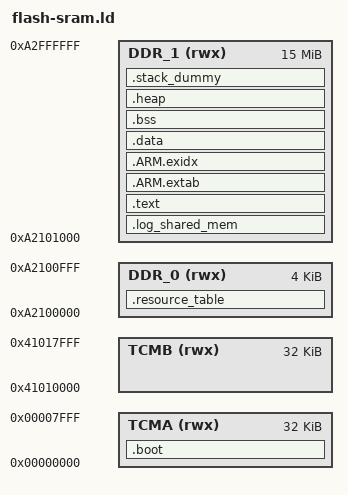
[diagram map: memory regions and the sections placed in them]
/****************************************************************************
 * boards/arm/k5-j721e/beaglebone-ai64-k5/scripts/flash-sram.ld
 *
 * Licensed to the Apache Software Foundation (ASF) under one or more
 * contributor license agreements.  See the NOTICE file distributed with
 * this work for additional information regarding copyright ownership.  The
 * ASF licenses this file to you under the Apache License, Version 2.0 (the
 * "License"); you may not use this file except in compliance with the
 * License.  You may obtain a copy of the License at
 *
 *   http://www.apache.org/licenses/LICENSE-2.0
 *
 * Unless required by applicable law or agreed to in writing, software
 * distributed under the License is distributed on an "AS IS" BASIS, WITHOUT
 * WARRANTIES OR CONDITIONS OF ANY KIND, either express or implied.  See the
 * License for the specific language governing permissions and limitations
 * under the License.
 *
 ****************************************************************************/

__DDR_START__ = 0xA2000000;

MEMORY
{
  TCMA (rwx) : ORIGIN = 0x00000000, LENGTH = 32K
  TCMB (rwx) : ORIGIN = 0x41010000, LENGTH = 32K
  /* MSRAM (rwx) : ORIGIN = 0x70000000, LENGTH = 16K */
  DDR_0 (rwx) : ORIGIN = __DDR_START__ + 0x100000, LENGTH = 4K
  DDR_1 (rwx) : ORIGIN = __DDR_START__ + 0x101000, LENGTH = 0xEFF000
}

EXTERN(_vectors)
ENTRY(_stext)

SECTIONS
{
	.boot :
	{
		KEEP(*(.vector))
		*(.boot*)
		*(.text.mpu*)
		*(.text.cache*)
		*(.text.boot*)
		*(.text.hwi*)
	} > TCMA

	.resource_table :
	{
		*(.resource_table*)
	} > DDR_0

	.log_shared_mem :
	{
		*(.log_shared_mem*)
	} > DDR_1
	
	.text :
	{
		
		*(.text*)

		KEEP(*(.init))
		KEEP(*(.fini))

		/* .ctors */
		*crtbegin.o(.ctors)
		*crtbegin?.o(.ctors)
		*(EXCLUDE_FILE(*crtend?.o *crtend.o) .ctors)
		*(SORT(.ctors.*))
		*(.ctors)

		/* .dtors */
 		*crtbegin.o(.dtors)
 		*crtbegin?.o(.dtors)
 		*(EXCLUDE_FILE(*crtend?.o *crtend.o) .dtors)
 		*(SORT(.dtors.*))
 		*(.dtors)

		*(.rodata*)

		KEEP(*(.eh_frame*))
	} > DDR_1

	.ARM.extab : 
	{
		*(.ARM.extab* .gnu.linkonce.armextab.*)
	} > DDR_1

	__exidx_start = .;
	.ARM.exidx :
	{
		*(.ARM.exidx* .gnu.linkonce.armexidx.*)
	} > DDR_1
	__exidx_end = .;

	/* To copy multiple ROM to RAM sections,
	 * uncomment .copy.table section and,
	 * define __STARTUP_COPY_MULTIPLE in startup_ARMCMx.S */
	/*
	.copy.table :
	{
		. = ALIGN(4);
		__copy_table_start__ = .;
		LONG (__etext)
		LONG (__data_start__)
		LONG (__data_end__ - __data_start__)
		LONG (__etext2)
		LONG (__data2_start__)
		LONG (__data2_end__ - __data2_start__)
		__copy_table_end__ = .;
	} > FLASH
	*/

	/* To clear multiple BSS sections,
	 * uncomment .zero.table section and,
	 * define __STARTUP_CLEAR_BSS_MULTIPLE in startup_ARMCMx.S */
	/*
	.zero.table :
	{
		. = ALIGN(4);
		__zero_table_start__ = .;
		LONG (__bss_start__)
		LONG (__bss_end__ - __bss_start__)
		LONG (__bss2_start__)
		LONG (__bss2_end__ - __bss2_start__)
		__zero_table_end__ = .;
	} > FLASH
	*/

	/* Location counter can end up 2byte aligned with narrow Thumb code but
	   __etext is assumed by startup code to be the LMA of a section in RAM
	   which must be 4byte aligned */
	__etext = ALIGN (4);

    _eronly = ABSOLUTE(.);

	.data : AT (__etext)
	{
        _sdata = ABSOLUTE(.);
		__data_start__ = .;
		*(vtable)
		*(.data*)

		. = ALIGN(4);
		/* preinit data */
		PROVIDE_HIDDEN (__preinit_array_start = .);
		KEEP(*(.preinit_array))
		PROVIDE_HIDDEN (__preinit_array_end = .);

		. = ALIGN(4);
		/* init data */
		PROVIDE_HIDDEN (__init_array_start = .);
		KEEP(*(SORT(.init_array.*)))
		KEEP(*(.init_array))
		PROVIDE_HIDDEN (__init_array_end = .);


		. = ALIGN(4);
		/* finit data */
		PROVIDE_HIDDEN (__fini_array_start = .);
		KEEP(*(SORT(.fini_array.*)))
		KEEP(*(.fini_array))
		PROVIDE_HIDDEN (__fini_array_end = .);

		KEEP(*(.jcr*))
		. = ALIGN(4);
		/* All data end */
		__data_end__ = .;
        _edata = ABSOLUTE(.);

	} > DDR_1

	.bss :
	{
		. = ALIGN(4);
        _sbss = ABSOLUTE(.);        
		__bss_start__ = .;
		*(.bss*)
		*(COMMON)
		. = ALIGN(4);
		__bss_end__ = .;
        _ebss = ABSOLUTE(.);
	} > DDR_1

	
	
	.heap (COPY):
	{
		__end__ = .;
		PROVIDE(end = .);
		*(.heap*)
		__HeapLimit = .;
	} > DDR_1

	/* .stack_dummy section doesn't contains any symbols. It is only
	 * used for linker to calculate size of stack sections, and assign
	 * values to stack symbols later */
	.stack_dummy (COPY):
	{
		*(.stack*)
	} > DDR_1

	/* Set stack top to end of RAM, and stack limit move down by
	 * size of stack_dummy section */
	__StackTop = ORIGIN(DDR_1) + LENGTH(DDR_1);
	__StackLimit = __StackTop - SIZEOF(.stack_dummy);
	PROVIDE(__stack = __StackTop);
	
	/* Check if data + heap + stack exceeds RAM limit */
	ASSERT(__StackLimit >= __HeapLimit, "region TCMA overflowed with stack")
}
